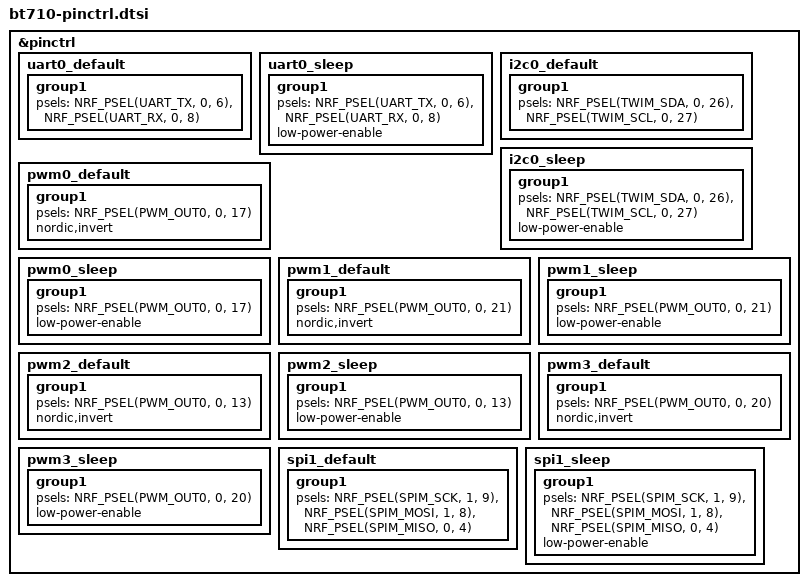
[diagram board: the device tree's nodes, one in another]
/*
 * Copyright (c) 2022 Nordic Semiconductor
 * SPDX-License-Identifier: Apache-2.0
 */

&pinctrl {
	uart0_default: uart0_default {
		group1 {
			psels = <NRF_PSEL(UART_TX, 0, 6)>,
				<NRF_PSEL(UART_RX, 0, 8)>;
		};
	};

	uart0_sleep: uart0_sleep {
		group1 {
			psels = <NRF_PSEL(UART_TX, 0, 6)>,
				<NRF_PSEL(UART_RX, 0, 8)>;
			low-power-enable;
		};
	};

	i2c0_default: i2c0_default {
		group1 {
			psels = <NRF_PSEL(TWIM_SDA, 0, 26)>,
				<NRF_PSEL(TWIM_SCL, 0, 27)>;
		};
	};

	i2c0_sleep: i2c0_sleep {
		group1 {
			psels = <NRF_PSEL(TWIM_SDA, 0, 26)>,
				<NRF_PSEL(TWIM_SCL, 0, 27)>;
			low-power-enable;
		};
	};

	pwm0_default: pwm0_default {
		group1 {
			psels = <NRF_PSEL(PWM_OUT0, 0, 17)>;
			nordic,invert;
		};
	};

	pwm0_sleep: pwm0_sleep {
		group1 {
			psels = <NRF_PSEL(PWM_OUT0, 0, 17)>;
			low-power-enable;
		};
	};

	pwm1_default: pwm1_default {
		group1 {
			psels = <NRF_PSEL(PWM_OUT0, 0, 21)>;
			nordic,invert;
		};
	};

	pwm1_sleep: pwm1_sleep {
		group1 {
			psels = <NRF_PSEL(PWM_OUT0, 0, 21)>;
			low-power-enable;
		};
	};

	pwm2_default: pwm2_default {
		group1 {
			psels = <NRF_PSEL(PWM_OUT0, 0, 13)>;
			nordic,invert;
		};
	};

	pwm2_sleep: pwm2_sleep {
		group1 {
			psels = <NRF_PSEL(PWM_OUT0, 0, 13)>;
			low-power-enable;
		};
	};

	pwm3_default: pwm3_default {
		group1 {
			psels = <NRF_PSEL(PWM_OUT0, 0, 20)>;
			nordic,invert;
		};
	};

	pwm3_sleep: pwm3_sleep {
		group1 {
			psels = <NRF_PSEL(PWM_OUT0, 0, 20)>;
			low-power-enable;
		};
	};

	spi1_default: spi1_default {
		group1 {
			psels = <NRF_PSEL(SPIM_SCK, 1, 9)>,
				<NRF_PSEL(SPIM_MOSI, 1, 8)>,
				<NRF_PSEL(SPIM_MISO, 0, 4)>;
		};
	};

	spi1_sleep: spi1_sleep {
		group1 {
			psels = <NRF_PSEL(SPIM_SCK, 1, 9)>,
				<NRF_PSEL(SPIM_MOSI, 1, 8)>,
				<NRF_PSEL(SPIM_MISO, 0, 4)>;
			low-power-enable;
		};
	};
};
